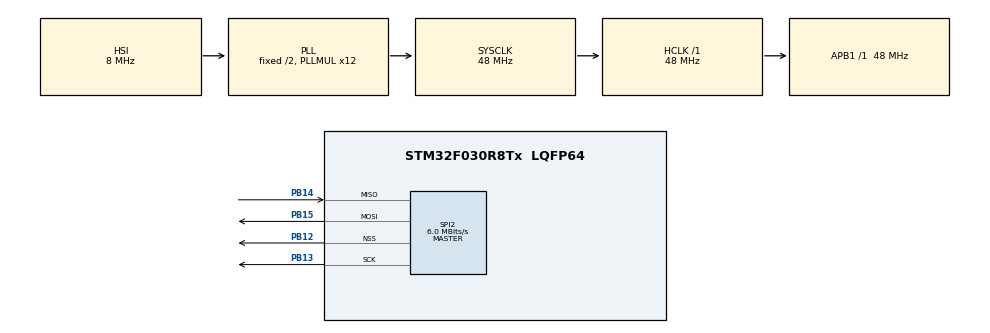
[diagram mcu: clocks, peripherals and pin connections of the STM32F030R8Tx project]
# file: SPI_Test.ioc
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Mcu.Family=STM32F0
Mcu.Name=STM32F030R8Tx
Mcu.Package=LQFP64
PA13.Mode=Serial_Wire
PA13.Signal=SYS_SWDIO
PA14.Mode=Serial_Wire
PA14.Signal=SYS_SWCLK
PB12.Mode=NSS_Signal_Hard_Output
PB12.Signal=SPI2_NSS
PB13.Mode=Full_Duplex_Master
PB13.Signal=SPI2_SCK
PB14.Mode=Full_Duplex_Master
PB14.Signal=SPI2_MISO
PB15.Mode=Full_Duplex_Master
PB15.Signal=SPI2_MOSI
ProjectManager.HeapSize=0x200
ProjectManager.StackSize=0x400
ProjectManager.TargetToolchain=STM32CubeIDE
RCC.AHBFreq_Value=48000000
RCC.APB1Freq_Value=48000000
RCC.APB1TimFreq_Value=48000000
RCC.HCLKFreq_Value=48000000
RCC.PLLMUL=RCC_PLL_MUL12
RCC.SYSCLKFreq_VALUE=48000000
RCC.SYSCLKSource=RCC_SYSCLKSOURCE_PLLCLK
SPI2.BaudRatePrescaler=SPI_BAUDRATEPRESCALER_8
SPI2.CalculateBaudRate=6.0 MBits/s
SPI2.DataSize=SPI_DATASIZE_8BIT
SPI2.Direction=SPI_DIRECTION_2LINES
SPI2.Mode=SPI_MODE_MASTER
SPI2.VirtualNSS=VM_NSSHARD
SPI2.VirtualType=VM_MASTER
board=NUCLEO-F030R8

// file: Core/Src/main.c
/* USER CODE BEGIN Header */
/**
  ******************************************************************************
  * @file           : main.c
  * @brief          : Main program body
  ******************************************************************************
  * @attention
  *
  * Copyright (c) 2026 STMicroelectronics.
  * All rights reserved.
  *
  * This software is licensed under terms that can be found in the LICENSE file
  * in the root directory of this software component.
  * If no LICENSE file comes with this software, it is provided AS-IS.
  *
  ******************************************************************************
  */
/* USER CODE END Header */
#include "main.h"

SPI_HandleTypeDef hspi2;

/* USER CODE BEGIN PV */
uint8_t TX_Data[]={1,2,3,4,5};
uint8_t RX_Data[5];
/* USER CODE END PV */

void SystemClock_Config(void);
static void MX_GPIO_Init(void);
static void MX_SPI2_Init(void);

/* USER CODE BEGIN 0 */
//DENEME
/* USER CODE END 0 */

int main(void)
{

  /* MCU Configuration--------------------------------------------------------*/

  /* Reset of all peripherals, Initializes the Flash interface and the Systick. */
  HAL_Init();

  /* Configure the system clock */
  SystemClock_Config();

  /* Initialize all configured peripherals */
  MX_GPIO_Init();
  MX_SPI2_Init();
  /* USER CODE BEGIN 2 */
  //burada chipselect pini resetlenir
  HAL_SPI_TransmitReceive(&hspi2, TX_Data, RX_Data, sizeof(TX_Data), HAL_MAX_DELAY);
  //burada chipselect pini set edilir
  /* USER CODE END 2 */

  /* Infinite loop */
  while (1)
  {

  }
}

void SystemClock_Config(void)
{
  RCC_OscInitTypeDef RCC_OscInitStruct = {0};
  RCC_ClkInitTypeDef RCC_ClkInitStruct = {0};

  /** Initializes the RCC Oscillators according to the specified parameters
  * in the RCC_OscInitTypeDef structure.
  */
  RCC_OscInitStruct.OscillatorType = RCC_OSCILLATORTYPE_HSI;
  RCC_OscInitStruct.HSIState = RCC_HSI_ON;
  RCC_OscInitStruct.HSICalibrationValue = RCC_HSICALIBRATION_DEFAULT;
  RCC_OscInitStruct.PLL.PLLState = RCC_PLL_ON;
  RCC_OscInitStruct.PLL.PLLSource = RCC_PLLSOURCE_HSI;
  RCC_OscInitStruct.PLL.PLLMUL = RCC_PLL_MUL12;
  RCC_OscInitStruct.PLL.PREDIV = RCC_PREDIV_DIV1;
  if (HAL_RCC_OscConfig(&RCC_OscInitStruct) != HAL_OK)
  {
    Error_Handler();
  }

  /** Initializes the CPU, AHB and APB buses clocks
  */
  RCC_ClkInitStruct.ClockType = RCC_CLOCKTYPE_HCLK|RCC_CLOCKTYPE_SYSCLK
                              |RCC_CLOCKTYPE_PCLK1;
  RCC_ClkInitStruct.SYSCLKSource = RCC_SYSCLKSOURCE_PLLCLK;
  RCC_ClkInitStruct.AHBCLKDivider = RCC_SYSCLK_DIV1;
  RCC_ClkInitStruct.APB1CLKDivider = RCC_HCLK_DIV1;

  if (HAL_RCC_ClockConfig(&RCC_ClkInitStruct, FLASH_LATENCY_1) != HAL_OK)
  {
    Error_Handler();
  }
}

static void MX_SPI2_Init(void)
{

  /* SPI2 parameter configuration*/
  hspi2.Instance = SPI2;
  hspi2.Init.Mode = SPI_MODE_MASTER;
  hspi2.Init.Direction = SPI_DIRECTION_2LINES;
  hspi2.Init.DataSize = SPI_DATASIZE_8BIT;
  hspi2.Init.CLKPolarity = SPI_POLARITY_LOW;
  hspi2.Init.CLKPhase = SPI_PHASE_1EDGE;
  hspi2.Init.NSS = SPI_NSS_HARD_OUTPUT;
  hspi2.Init.BaudRatePrescaler = SPI_BAUDRATEPRESCALER_8;
  hspi2.Init.FirstBit = SPI_FIRSTBIT_MSB;
  hspi2.Init.TIMode = SPI_TIMODE_DISABLE;
  hspi2.Init.CRCCalculation = SPI_CRCCALCULATION_DISABLE;
  hspi2.Init.CRCPolynomial = 7;
  hspi2.Init.CRCLength = SPI_CRC_LENGTH_DATASIZE;
  hspi2.Init.NSSPMode = SPI_NSS_PULSE_ENABLE;
  if (HAL_SPI_Init(&hspi2) != HAL_OK)
  {
    Error_Handler();
  }

}

static void MX_GPIO_Init(void)
{

  /* GPIO Ports Clock Enable */
  __HAL_RCC_GPIOB_CLK_ENABLE();
  __HAL_RCC_GPIOA_CLK_ENABLE();

}

void Error_Handler(void)
{
  __disable_irq();
  while (1)
  {
  }
}
